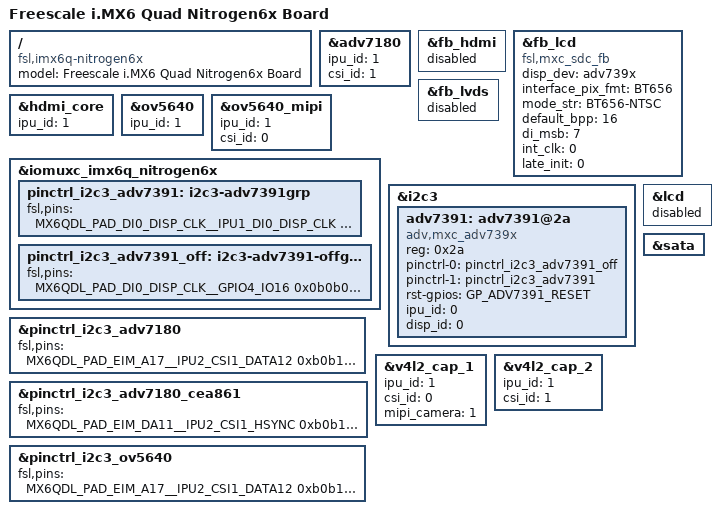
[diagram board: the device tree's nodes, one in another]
/*
 * Copyright 2015 Boundary Devices, Inc.
 * Copyright 2012 Freescale Semiconductor, Inc.
 * Copyright 2011 Linaro Ltd.
 *
 * The code contained herein is licensed under the GNU General Public
 * License. You may obtain a copy of the GNU General Public License
 * Version 2 or later at the following locations:
 *
 * http://www.opensource.org/licenses/gpl-license.html
 * http://www.gnu.org/copyleft/gpl.html
 */

/dts-v1/;

#include <dt-bindings/interrupt-controller/irq.h>
#include "imx6q.dtsi"
#include "imx6qdl-nitrogen6x.dtsi"

/ {
	model = "Freescale i.MX6 Quad Nitrogen6x Board";
	compatible = "fsl,imx6q-nitrogen6x", "fsl,imx6q";
};

&adv7180 {
	ipu_id = <1>;
	csi_id = <1>;
};

&fb_hdmi {
	status = "disabled";
};

&fb_lcd {
	compatible = "fsl,mxc_sdc_fb";
	disp_dev = "adv739x";
	interface_pix_fmt = "BT656";
	mode_str ="BT656-NTSC";
	default_bpp = <16>;
	di_msb = <7>;
	int_clk = <0>;
	late_init = <0>;
	status = "okay";
};

&fb_lvds {
	status = "disabled";
};

&hdmi_core {
	ipu_id = <1>;
};

&ov5640 {
	ipu_id = <1>;
};

&ov5640_mipi {
	ipu_id = <1>;
	csi_id = <0>;
};

&iomuxc_imx6q_nitrogen6x {
	pinctrl_i2c3_adv7391: i2c3-adv7391grp {
		fsl,pins = <
			MX6QDL_PAD_DI0_DISP_CLK__IPU1_DI0_DISP_CLK 0x10     /* Pixclk */
			MX6QDL_PAD_DISP0_DAT0__IPU1_DISP0_DATA00  0x10
			MX6QDL_PAD_DISP0_DAT1__IPU1_DISP0_DATA01  0x10
			MX6QDL_PAD_DISP0_DAT2__IPU1_DISP0_DATA02  0x10
			MX6QDL_PAD_DISP0_DAT3__IPU1_DISP0_DATA03  0x10
			MX6QDL_PAD_DISP0_DAT4__IPU1_DISP0_DATA04  0x10
			MX6QDL_PAD_DISP0_DAT5__IPU1_DISP0_DATA05  0x10
			MX6QDL_PAD_DISP0_DAT6__IPU1_DISP0_DATA06  0x10
			MX6QDL_PAD_DISP0_DAT7__IPU1_DISP0_DATA07  0x10
		>;
	};

	pinctrl_i2c3_adv7391_off: i2c3-adv7391-offgrp {
		fsl,pins = <
			MX6QDL_PAD_DI0_DISP_CLK__GPIO4_IO16 0x0b0b0	/* Pixclk */
			MX6QDL_PAD_DI0_PIN2__GPIO4_IO18     0x0b0b0	/* HSYNC */
			MX6QDL_PAD_DI0_PIN3__GPIO4_IO19     0x0b0b0	/* VSYNC */
			MX6QDL_PAD_DISP0_DAT0__GPIO4_IO21   0x0b0b0
			MX6QDL_PAD_DISP0_DAT1__GPIO4_IO22   0x0b0b0
			MX6QDL_PAD_DISP0_DAT2__GPIO4_IO23   0x0b0b0
			MX6QDL_PAD_DISP0_DAT3__GPIO4_IO24   0x0b0b0
			MX6QDL_PAD_DISP0_DAT4__GPIO4_IO25   0x0b0b0
			MX6QDL_PAD_DISP0_DAT5__GPIO4_IO26   0x0b0b0
			MX6QDL_PAD_DISP0_DAT6__GPIO4_IO27   0x0b0b0
			MX6QDL_PAD_DISP0_DAT7__GPIO4_IO28   0x0b0b0
#define GP_ADV7391_RESET	<&gpio4 20 GPIO_ACTIVE_LOW>
			MX6QDL_PAD_DI0_PIN4__GPIO4_IO20     0x030b0	/* reset */
		>;
	};
};

&i2c3 {
	adv7391: adv7391@2a {
		compatible = "adv,mxc_adv739x";
		reg = <0x2a>;
		pinctrl-names = "default", "enable";
		pinctrl-0 = <&pinctrl_i2c3_adv7391_off>;
		pinctrl-1 = <&pinctrl_i2c3_adv7391>;
		rst-gpios = GP_ADV7391_RESET;
		ipu_id = <0>;
		disp_id = <0>;
	};
};

&lcd {
	status = "disabled";
};

&pinctrl_i2c3_adv7180 {
	fsl,pins = <
		MX6QDL_PAD_EIM_A17__IPU2_CSI1_DATA12	0xb0b1
		MX6QDL_PAD_EIM_A18__IPU2_CSI1_DATA13	0xb0b1
		MX6QDL_PAD_EIM_A19__IPU2_CSI1_DATA14	0xb0b1
		MX6QDL_PAD_EIM_A20__IPU2_CSI1_DATA15	0xb0b1
		MX6QDL_PAD_EIM_A21__IPU2_CSI1_DATA16	0xb0b1
		MX6QDL_PAD_EIM_A22__IPU2_CSI1_DATA17	0xb0b1
		MX6QDL_PAD_EIM_A23__IPU2_CSI1_DATA18	0xb0b1
		MX6QDL_PAD_EIM_EB2__IPU2_CSI1_DATA19	0xb0b1
		MX6QDL_PAD_EIM_A16__IPU2_CSI1_PIXCLK	0xb0b1
       >;
};

&pinctrl_i2c3_adv7180_cea861 {
	fsl,pins = <
		MX6QDL_PAD_EIM_DA11__IPU2_CSI1_HSYNC	0xb0b1
		MX6QDL_PAD_EIM_DA12__IPU2_CSI1_VSYNC	0xb0b1
	>;
};

&pinctrl_i2c3_ov5640 { /* parallel camera */
	fsl,pins = <
		MX6QDL_PAD_EIM_A17__IPU2_CSI1_DATA12	0xb0b1
		MX6QDL_PAD_EIM_A18__IPU2_CSI1_DATA13	0xb0b1
		MX6QDL_PAD_EIM_A19__IPU2_CSI1_DATA14	0xb0b1
		MX6QDL_PAD_EIM_A20__IPU2_CSI1_DATA15	0xb0b1
		MX6QDL_PAD_EIM_A21__IPU2_CSI1_DATA16	0xb0b1
		MX6QDL_PAD_EIM_A22__IPU2_CSI1_DATA17	0xb0b1
		MX6QDL_PAD_EIM_A23__IPU2_CSI1_DATA18	0xb0b1
		MX6QDL_PAD_EIM_EB2__IPU2_CSI1_DATA19	0xb0b1
		MX6QDL_PAD_EIM_DA10__IPU2_CSI1_DATA_EN	0xb0b1
		MX6QDL_PAD_EIM_A16__IPU2_CSI1_PIXCLK	0xb0b1
		MX6QDL_PAD_EIM_DA11__IPU2_CSI1_HSYNC	0xb0b1
		MX6QDL_PAD_EIM_DA12__IPU2_CSI1_VSYNC	0xb0b1
	>;
};

&sata {
	status = "okay";
};

/* ov5640_mipi */
&v4l2_cap_1 {
	ipu_id = <1>;
	csi_id = <0>;
	mipi_camera = <1>;
};

/* adv7180, ov5640 */
&v4l2_cap_2 {
	ipu_id = <1>;
	csi_id = <1>;
};
